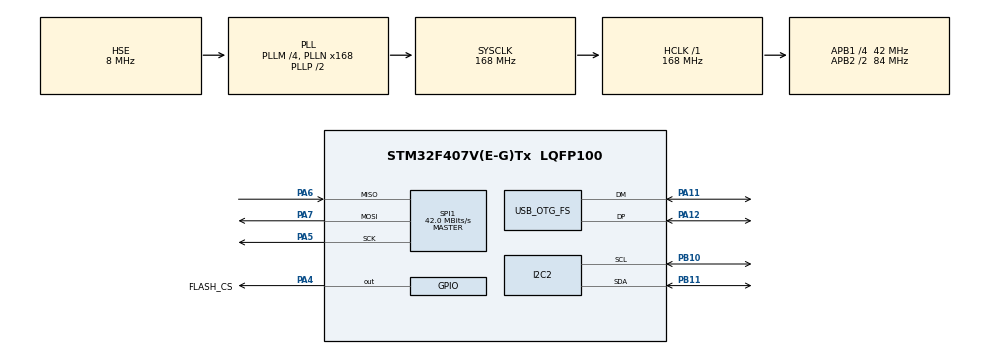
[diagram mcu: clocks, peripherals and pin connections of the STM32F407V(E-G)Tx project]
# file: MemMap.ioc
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Mcu.Family=STM32F4
Mcu.Name=STM32F407V(E-G)Tx
Mcu.Package=LQFP100
NVIC.OTG_FS_IRQn=true\:0\:0\:false\:false\:true\:false\:true\:true
NVIC.PriorityGroup=NVIC_PRIORITYGROUP_4
NimaLTD.I-CUBE-EE24.3.2.0.DriverJjEE24=true
NimaLTD.I-CUBE-EE24.3.2.0.EE24_SIZE=EE24_8KBIT
PA11.Mode=Device_Only
PA11.Signal=USB_OTG_FS_DM
PA12.Mode=Device_Only
PA12.Signal=USB_OTG_FS_DP
PA4.GPIO_Label=FLASH_CS
PA4.Signal=GPIO_Output
PA5.Mode=Full_Duplex_Master
PA5.Signal=SPI1_SCK
PA6.Mode=Full_Duplex_Master
PA6.Signal=SPI1_MISO
PA7.Mode=Full_Duplex_Master
PA7.Signal=SPI1_MOSI
PB10.GPIO_Pu=GPIO_PULLUP
PB10.Mode=I2C
PB10.Signal=I2C2_SCL
PB11.GPIO_Pu=GPIO_PULLUP
PB11.Mode=I2C
PB11.Signal=I2C2_SDA
PH0-OSC_IN.Mode=HSE-External-Oscillator
PH0-OSC_IN.Signal=RCC_OSC_IN
PH1-OSC_OUT.Mode=HSE-External-Oscillator
PH1-OSC_OUT.Signal=RCC_OSC_OUT
ProjectManager.HeapSize=0x200
ProjectManager.StackSize=0x400
ProjectManager.TargetToolchain=STM32CubeIDE
RCC.48MHZClocksFreq_Value=48000000
RCC.AHBFreq_Value=168000000
RCC.APB1CLKDivider=RCC_HCLK_DIV4
RCC.APB1Freq_Value=42000000
RCC.APB1TimFreq_Value=84000000
RCC.APB2CLKDivider=RCC_HCLK_DIV2
RCC.APB2Freq_Value=84000000
RCC.APB2TimFreq_Value=168000000
RCC.CortexFreq_Value=168000000
RCC.HCLKFreq_Value=168000000
RCC.HSE_VALUE=8000000
RCC.HSI_VALUE=16000000
RCC.LSE_VALUE=32768
RCC.PLLM=4
RCC.PLLN=168
RCC.PLLQ=7
RCC.SYSCLKFreq_VALUE=168000000
RCC.SYSCLKSource=RCC_SYSCLKSOURCE_PLLCLK
RCC.VCOOutputFreq_Value=336000000
SPI1.BaudRatePrescaler=SPI_BAUDRATEPRESCALER_2
SPI1.CalculateBaudRate=42.0 MBits/s
SPI1.Direction=SPI_DIRECTION_2LINES
SPI1.Mode=SPI_MODE_MASTER
SPI1.VirtualType=VM_MASTER
USB_DEVICE.CLASS_NAME_FS=MSC
USB_DEVICE.VirtualMode-MSC_FS=Msc
USB_DEVICE.VirtualModeFS=Msc_FS
USB_OTG_FS.VirtualMode=Device_Only
VP_FATFS_VS_Generic.Mode=User_defined
VP_NimaLTD.I-CUBE-EE24_VS_DriverJjEE24_1.0.0_3.2.0.Mode=DriverJjEE24
VP_USB_DEVICE_VS_USB_DEVICE_MSC_FS.Mode=MSC_FS
board=custom

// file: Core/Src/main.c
/* USER CODE BEGIN Header */
/**
  ******************************************************************************
  * @file           : main.c
  * @brief          : Main program body
  ******************************************************************************
  * @attention
  *
  * Copyright (c) 2024 STMicroelectronics.
  * All rights reserved.
  *
  * This software is licensed under terms that can be found in the LICENSE file
  * in the root directory of this software component.
  * If no LICENSE file comes with this software, it is provided AS-IS.
  *
  ******************************************************************************
  */
/* USER CODE END Header */
#include "main.h"
#include "usb_device.h"

I2C_HandleTypeDef hi2c2;

SPI_HandleTypeDef hspi1;

void SystemClock_Config(void);
static void MX_GPIO_Init(void);
static void MX_I2C2_Init(void);
static void MX_SPI1_Init(void);

int main(void)
{

  /* MCU Configuration--------------------------------------------------------*/

  /* Reset of all peripherals, Initializes the Flash interface and the Systick. */
  HAL_Init();

  /* Configure the system clock */
  SystemClock_Config();

  /* Initialize all configured peripherals */
  MX_GPIO_Init();
  MX_I2C2_Init();
  MX_USB_DEVICE_Init();
  MX_SPI1_Init();

  /* Infinite loop */
  while (1)
  {

  }
}

void SystemClock_Config(void)
{
  RCC_OscInitTypeDef RCC_OscInitStruct = {0};
  RCC_ClkInitTypeDef RCC_ClkInitStruct = {0};

  /** Configure the main internal regulator output voltage
  */
  __HAL_RCC_PWR_CLK_ENABLE();
  __HAL_PWR_VOLTAGESCALING_CONFIG(PWR_REGULATOR_VOLTAGE_SCALE1);

  /** Initializes the RCC Oscillators according to the specified parameters
  * in the RCC_OscInitTypeDef structure.
  */
  RCC_OscInitStruct.OscillatorType = RCC_OSCILLATORTYPE_HSE;
  RCC_OscInitStruct.HSEState = RCC_HSE_ON;
  RCC_OscInitStruct.PLL.PLLState = RCC_PLL_ON;
  RCC_OscInitStruct.PLL.PLLSource = RCC_PLLSOURCE_HSE;
  RCC_OscInitStruct.PLL.PLLM = 4;
  RCC_OscInitStruct.PLL.PLLN = 168;
  RCC_OscInitStruct.PLL.PLLP = RCC_PLLP_DIV2;
  RCC_OscInitStruct.PLL.PLLQ = 7;
  if (HAL_RCC_OscConfig(&RCC_OscInitStruct) != HAL_OK)
  {
    Error_Handler();
  }

  /** Initializes the CPU, AHB and APB buses clocks
  */
  RCC_ClkInitStruct.ClockType = RCC_CLOCKTYPE_HCLK|RCC_CLOCKTYPE_SYSCLK
                              |RCC_CLOCKTYPE_PCLK1|RCC_CLOCKTYPE_PCLK2;
  RCC_ClkInitStruct.SYSCLKSource = RCC_SYSCLKSOURCE_PLLCLK;
  RCC_ClkInitStruct.AHBCLKDivider = RCC_SYSCLK_DIV1;
  RCC_ClkInitStruct.APB1CLKDivider = RCC_HCLK_DIV4;
  RCC_ClkInitStruct.APB2CLKDivider = RCC_HCLK_DIV2;

  if (HAL_RCC_ClockConfig(&RCC_ClkInitStruct, FLASH_LATENCY_5) != HAL_OK)
  {
    Error_Handler();
  }
}

static void MX_I2C2_Init(void)
{

  hi2c2.Instance = I2C2;
  hi2c2.Init.ClockSpeed = 100000;
  hi2c2.Init.DutyCycle = I2C_DUTYCYCLE_2;
  hi2c2.Init.OwnAddress1 = 0;
  hi2c2.Init.AddressingMode = I2C_ADDRESSINGMODE_7BIT;
  hi2c2.Init.DualAddressMode = I2C_DUALADDRESS_DISABLE;
  hi2c2.Init.OwnAddress2 = 0;
  hi2c2.Init.GeneralCallMode = I2C_GENERALCALL_DISABLE;
  hi2c2.Init.NoStretchMode = I2C_NOSTRETCH_DISABLE;
  if (HAL_I2C_Init(&hi2c2) != HAL_OK)
  {
    Error_Handler();
  }

}

static void MX_SPI1_Init(void)
{

  /* SPI1 parameter configuration*/
  hspi1.Instance = SPI1;
  hspi1.Init.Mode = SPI_MODE_MASTER;
  hspi1.Init.Direction = SPI_DIRECTION_2LINES;
  hspi1.Init.DataSize = SPI_DATASIZE_8BIT;
  hspi1.Init.CLKPolarity = SPI_POLARITY_LOW;
  hspi1.Init.CLKPhase = SPI_PHASE_1EDGE;
  hspi1.Init.NSS = SPI_NSS_SOFT;
  hspi1.Init.BaudRatePrescaler = SPI_BAUDRATEPRESCALER_2;
  hspi1.Init.FirstBit = SPI_FIRSTBIT_MSB;
  hspi1.Init.TIMode = SPI_TIMODE_DISABLE;
  hspi1.Init.CRCCalculation = SPI_CRCCALCULATION_DISABLE;
  hspi1.Init.CRCPolynomial = 10;
  if (HAL_SPI_Init(&hspi1) != HAL_OK)
  {
    Error_Handler();
  }

}

static void MX_GPIO_Init(void)
{
  GPIO_InitTypeDef GPIO_InitStruct = {0};

  /* GPIO Ports Clock Enable */
  __HAL_RCC_GPIOH_CLK_ENABLE();
  __HAL_RCC_GPIOA_CLK_ENABLE();
  __HAL_RCC_GPIOB_CLK_ENABLE();

  /*Configure GPIO pin Output Level */
  HAL_GPIO_WritePin(FLASH_CS_GPIO_Port, FLASH_CS_Pin, GPIO_PIN_RESET);

  /*Configure GPIO pin : FLASH_CS_Pin */
  GPIO_InitStruct.Pin = FLASH_CS_Pin;
  GPIO_InitStruct.Mode = GPIO_MODE_OUTPUT_PP;
  GPIO_InitStruct.Pull = GPIO_NOPULL;
  GPIO_InitStruct.Speed = GPIO_SPEED_FREQ_LOW;
  HAL_GPIO_Init(FLASH_CS_GPIO_Port, &GPIO_InitStruct);

}

/* USER CODE BEGIN 4 */
void USB_STATE_Changed(uint8_t dev_state, uint8_t dev_old_state){

}
/* USER CODE END 4 */

void Error_Handler(void)
{
  __disable_irq();
  while (1)
  {
  }
}
